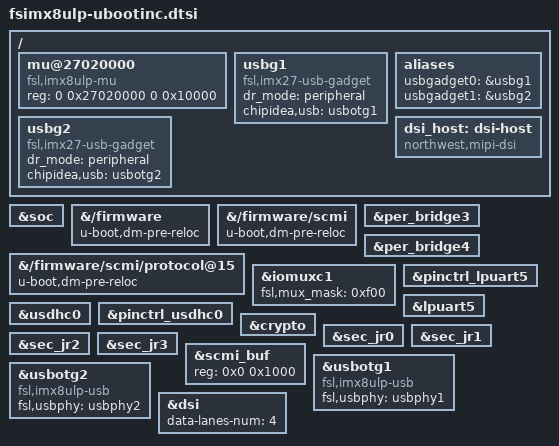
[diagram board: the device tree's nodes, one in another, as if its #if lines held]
/*
 * Copyright (C) 2024 F&S Elektronik Systeme GmbH
 *
 * This program is free software; you can redistribute it and/or modify
 * it under the terms of the GNU General Public License version 2 as
 * published by the Free Software Foundation.
 */

/ {
	mu@27020000 {
		compatible = "fsl,imx8ulp-mu";
		reg = <0 0x27020000 0 0x10000>;
		status = "okay";
		u-boot,dm-spl;
	};

#if defined(CONFIG_PICOCOREMX8ULP_USB_OTG) || defined(CONFIG_SOLDERCORE8ULP_USB0)
	usbg1: usbg1 {
		compatible = "fsl,imx27-usb-gadget";
		dr_mode = "peripheral";
		chipidea,usb = <&usbotg1>;
		status = "okay";
	};

	aliases {
		usbgadget0 = &usbg1;
	};
#endif

#if defined(CONFIG_SOLDERCORE8ULP_USB1)
	usbg2: usbg2 {
		compatible = "fsl,imx27-usb-gadget";
		dr_mode = "peripheral";
		chipidea,usb = <&usbotg2>;
		status = "okay";
	};

	aliases {
		usbgadget1 = &usbg2;
	};
#endif

#if defined(CONFIG_SOLDERCORE8ULP_MIPI_DSI_UBOOT)
dsi_host: dsi-host {
		compatible = "northwest,mipi-dsi";
		status = "okay";
	};
#endif
};

&soc {
	u-boot,dm-spl;
};

&{/firmware} {
	u-boot,dm-pre-reloc;
};

&{/firmware/scmi} {
	u-boot,dm-pre-reloc;
};

&{/firmware/scmi/protocol@15} {
	u-boot,dm-pre-reloc;
};

&per_bridge3 {
	u-boot,dm-spl;
};

&per_bridge4 {
	u-boot,dm-spl;
};

&iomuxc1 {
	u-boot,dm-spl;
	fsl,mux_mask = <0xf00>;
};

&pinctrl_lpuart5 {
	u-boot,dm-spl;
};

&lpuart5 {
	u-boot,dm-spl;
};

&usdhc0 {
	u-boot,dm-spl;
};

&pinctrl_usdhc0 {
	u-boot,dm-spl;
};

&crypto {
	u-boot,dm-spl;
};

&sec_jr0 {
	u-boot,dm-spl;
};

&sec_jr1 {
	u-boot,dm-spl;
};

&sec_jr2 {
	u-boot,dm-spl;
};

&sec_jr3 {
	u-boot,dm-spl;
};

&scmi_buf {
	reg = <0x0 0x1000>; /* Align page size */
};

&usbotg1 {
	compatible = "fsl,imx8ulp-usb", "fsl,imx7ulp-usb", "fsl,imx27-usb";
	fsl,usbphy = <&usbphy1>;
};

&usbotg2 {
	compatible = "fsl,imx8ulp-usb", "fsl,imx7ulp-usb", "fsl,imx27-usb";
	fsl,usbphy = <&usbphy2>;
};

#if defined(CONFIG_SOLDERCORE8ULP_MIPI_DSI_UBOOT)
&dsi {
	data-lanes-num = <4>;
};
#endif
